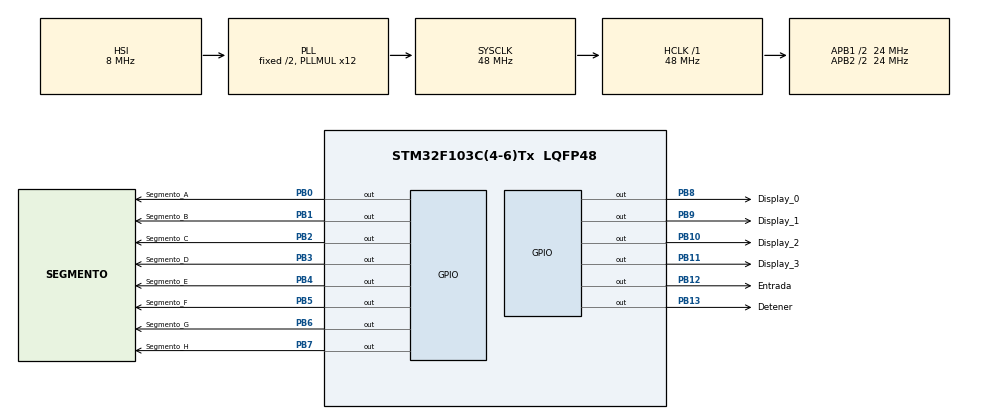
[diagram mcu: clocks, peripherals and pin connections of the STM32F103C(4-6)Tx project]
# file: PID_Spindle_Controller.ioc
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Mcu.Family=STM32F1
Mcu.Name=STM32F103C(4-6)Tx
Mcu.Package=LQFP48
NVIC.PriorityGroup=NVIC_PRIORITYGROUP_4
PB0.GPIO_Label=Segmento_A
PB0.Signal=GPIO_Output
PB1.GPIO_Label=Segmento_B
PB1.Signal=GPIO_Output
PB10.GPIO_Label=Display_2
PB10.Signal=GPIO_Output
PB11.GPIO_Label=Display_3
PB11.Signal=GPIO_Output
PB12.GPIO_Label=Entrada
PB12.Signal=GPIO_Output
PB13.GPIO_Label=Detener
PB13.Signal=GPIO_Output
PB2.GPIO_Label=Segmento_C
PB2.Signal=GPIO_Output
PB3.GPIO_Label=Segmento_D
PB3.Signal=GPIO_Output
PB4.GPIO_Label=Segmento_E
PB4.Signal=GPIO_Output
PB5.GPIO_Label=Segmento_F
PB5.Signal=GPIO_Output
PB6.GPIO_Label=Segmento_G
PB6.Signal=GPIO_Output
PB7.GPIO_Label=Segmento_H
PB7.Signal=GPIO_Output
PB8.GPIO_Label=Display_0
PB8.Signal=GPIO_Output
PB9.GPIO_Label=Display_1
PB9.Signal=GPIO_Output
ProjectManager.HeapSize=0x200
ProjectManager.StackSize=0x400
ProjectManager.TargetToolchain=STM32CubeIDE
RCC.AHBFreq_Value=48000000
RCC.APB1CLKDivider=RCC_HCLK_DIV2
RCC.APB1Freq_Value=24000000
RCC.APB1TimFreq_Value=48000000
RCC.APB2CLKDivider=RCC_HCLK_DIV2
RCC.APB2Freq_Value=24000000
RCC.APB2TimFreq_Value=48000000
RCC.HCLKFreq_Value=48000000
RCC.PLLMUL=RCC_PLL_MUL12
RCC.SYSCLKFreq_VALUE=48000000
RCC.SYSCLKSource=RCC_SYSCLKSOURCE_PLLCLK
RCC.USBFreq_Value=48000000
TIM2.Period=4096
TIM2.Prescaler=45000-1
VP_SYS_VS_ND.Mode=No_Debug
VP_TIM2_VS_ClockSourceINT.Mode=Internal
board=custom

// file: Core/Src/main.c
/* USER CODE BEGIN Header */
/**
  ******************************************************************************
  * @file           : main.c
  * @brief          : Main program body
  ******************************************************************************
  * @attention
  *
  * <h2><center>&copy; Copyright (c) 2020 STMicroelectronics.
  * All rights reserved.</center></h2>
  *
  * This software component is licensed by ST under BSD 3-Clause license,
  * the "License"; You may not use this file except in compliance with the
  * License. You may obtain a copy of the License at:
  *                        opensource.org/licenses/BSD-3-Clause
  *
  ******************************************************************************
  */
/* USER CODE END Header */

#include "main.h"

/* USER CODE BEGIN Includes */
#include "../Aplicaciones/Librerias.h"
/* USER CODE END Includes */

TIM_HandleTypeDef htim2;

void SystemClock_Config(void);
static void MX_GPIO_Init(void);
static void MX_TIM2_Init(void);

int main(void)
{

  /* MCU Configuration--------------------------------------------------------*/

  /* Reset of all peripherals, Initializes the Flash interface and the Systick. */
  HAL_Init();

  /* Configure the system clock */
  SystemClock_Config();

  /* Initialize all configured peripherals */
  MX_GPIO_Init();
  MX_TIM2_Init();

  /* Infinite loop */
  /* USER CODE BEGIN WHILE */
  while (1)
  {
	  app_Tacometro();
    /* USER CODE END WHILE */

  }
}

void SystemClock_Config(void)
{
  RCC_OscInitTypeDef RCC_OscInitStruct = {0};
  RCC_ClkInitTypeDef RCC_ClkInitStruct = {0};

  /** Initializes the CPU, AHB and APB busses clocks
  */
  RCC_OscInitStruct.OscillatorType = RCC_OSCILLATORTYPE_HSI;
  RCC_OscInitStruct.HSIState = RCC_HSI_ON;
  RCC_OscInitStruct.HSICalibrationValue = RCC_HSICALIBRATION_DEFAULT;
  RCC_OscInitStruct.PLL.PLLState = RCC_PLL_ON;
  RCC_OscInitStruct.PLL.PLLSource = RCC_PLLSOURCE_HSI_DIV2;
  RCC_OscInitStruct.PLL.PLLMUL = RCC_PLL_MUL12;
  if (HAL_RCC_OscConfig(&RCC_OscInitStruct) != HAL_OK)
  {
    Error_Handler();
  }
  /** Initializes the CPU, AHB and APB busses clocks
  */
  RCC_ClkInitStruct.ClockType = RCC_CLOCKTYPE_HCLK|RCC_CLOCKTYPE_SYSCLK
                              |RCC_CLOCKTYPE_PCLK1|RCC_CLOCKTYPE_PCLK2;
  RCC_ClkInitStruct.SYSCLKSource = RCC_SYSCLKSOURCE_PLLCLK;
  RCC_ClkInitStruct.AHBCLKDivider = RCC_SYSCLK_DIV1;
  RCC_ClkInitStruct.APB1CLKDivider = RCC_HCLK_DIV2;
  RCC_ClkInitStruct.APB2CLKDivider = RCC_HCLK_DIV2;

  if (HAL_RCC_ClockConfig(&RCC_ClkInitStruct, FLASH_LATENCY_1) != HAL_OK)
  {
    Error_Handler();
  }
}

static void MX_TIM2_Init(void)
{

  TIM_ClockConfigTypeDef sClockSourceConfig = {0};
  TIM_MasterConfigTypeDef sMasterConfig = {0};

  htim2.Instance = TIM2;
  htim2.Init.Prescaler = 45000-1;
  htim2.Init.CounterMode = TIM_COUNTERMODE_UP;
  htim2.Init.Period = 4096;
  htim2.Init.ClockDivision = TIM_CLOCKDIVISION_DIV1;
  htim2.Init.AutoReloadPreload = TIM_AUTORELOAD_PRELOAD_DISABLE;
  if (HAL_TIM_Base_Init(&htim2) != HAL_OK)
  {
    Error_Handler();
  }
  sClockSourceConfig.ClockSource = TIM_CLOCKSOURCE_INTERNAL;
  if (HAL_TIM_ConfigClockSource(&htim2, &sClockSourceConfig) != HAL_OK)
  {
    Error_Handler();
  }
  sMasterConfig.MasterOutputTrigger = TIM_TRGO_RESET;
  sMasterConfig.MasterSlaveMode = TIM_MASTERSLAVEMODE_DISABLE;
  if (HAL_TIMEx_MasterConfigSynchronization(&htim2, &sMasterConfig) != HAL_OK)
  {
    Error_Handler();
  }

}

static void MX_GPIO_Init(void)
{
  GPIO_InitTypeDef GPIO_InitStruct = {0};

  /* GPIO Ports Clock Enable */
  __HAL_RCC_GPIOB_CLK_ENABLE();

  /*Configure GPIO pin Output Level */
  HAL_GPIO_WritePin(GPIOB, Segmento_A_Pin|Segmento_B_Pin|Segmento_C_Pin|Display_2_Pin
                          |Display_3_Pin|Entrada_Pin|Detener_Pin|Segmento_D_Pin
                          |Segmento_E_Pin|Segmento_F_Pin|Segmento_G_Pin|Segmento_H_Pin
                          |Display_0_Pin|Display_1_Pin, GPIO_PIN_RESET);

  /*Configure GPIO pins : Segmento_A_Pin Segmento_B_Pin Segmento_C_Pin Display_2_Pin
                           Display_3_Pin Entrada_Pin Detener_Pin Segmento_D_Pin
                           Segmento_E_Pin Segmento_F_Pin Segmento_G_Pin Segmento_H_Pin
                           Display_0_Pin Display_1_Pin */
  GPIO_InitStruct.Pin = Segmento_A_Pin|Segmento_B_Pin|Segmento_C_Pin|Display_2_Pin
                          |Display_3_Pin|Entrada_Pin|Detener_Pin|Segmento_D_Pin
                          |Segmento_E_Pin|Segmento_F_Pin|Segmento_G_Pin|Segmento_H_Pin
                          |Display_0_Pin|Display_1_Pin;
  GPIO_InitStruct.Mode = GPIO_MODE_OUTPUT_PP;
  GPIO_InitStruct.Pull = GPIO_NOPULL;
  GPIO_InitStruct.Speed = GPIO_SPEED_FREQ_LOW;
  HAL_GPIO_Init(GPIOB, &GPIO_InitStruct);

}

void Error_Handler(void)
{
}

/************************ (C) COPYRIGHT STMicroelectronics *****END OF FILE****/
